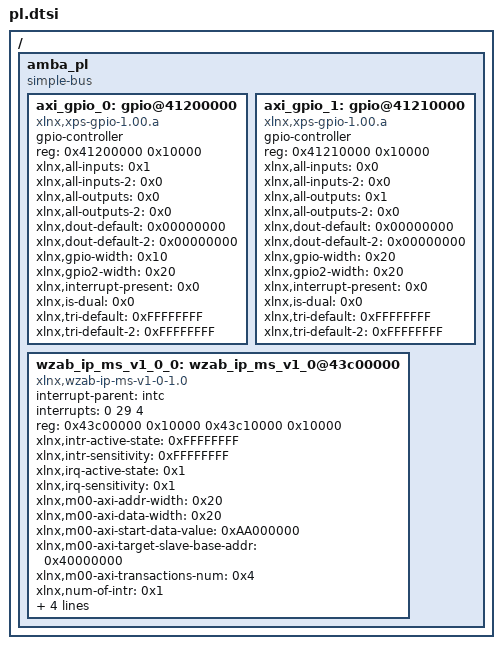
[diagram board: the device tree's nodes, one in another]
/*
 * CAUTION: This file is automatically generated by Xilinx.
 * Version:  
 * Today is: Fri Aug 12 16:10:27 2016
*/


/ {
	amba_pl: amba_pl {
		#address-cells = <1>;
		#size-cells = <1>;
		compatible = "simple-bus";
		ranges ;
		axi_gpio_0: gpio@41200000 {
			#gpio-cells = <2>;
			compatible = "xlnx,xps-gpio-1.00.a";
			gpio-controller ;
			reg = <0x41200000 0x10000>;
			xlnx,all-inputs = <0x1>;
			xlnx,all-inputs-2 = <0x0>;
			xlnx,all-outputs = <0x0>;
			xlnx,all-outputs-2 = <0x0>;
			xlnx,dout-default = <0x00000000>;
			xlnx,dout-default-2 = <0x00000000>;
			xlnx,gpio-width = <0x10>;
			xlnx,gpio2-width = <0x20>;
			xlnx,interrupt-present = <0x0>;
			xlnx,is-dual = <0x0>;
			xlnx,tri-default = <0xFFFFFFFF>;
			xlnx,tri-default-2 = <0xFFFFFFFF>;
		};
		axi_gpio_1: gpio@41210000 {
			#gpio-cells = <2>;
			compatible = "xlnx,xps-gpio-1.00.a";
			gpio-controller ;
			reg = <0x41210000 0x10000>;
			xlnx,all-inputs = <0x0>;
			xlnx,all-inputs-2 = <0x0>;
			xlnx,all-outputs = <0x1>;
			xlnx,all-outputs-2 = <0x0>;
			xlnx,dout-default = <0x00000000>;
			xlnx,dout-default-2 = <0x00000000>;
			xlnx,gpio-width = <0x20>;
			xlnx,gpio2-width = <0x20>;
			xlnx,interrupt-present = <0x0>;
			xlnx,is-dual = <0x0>;
			xlnx,tri-default = <0xFFFFFFFF>;
			xlnx,tri-default-2 = <0xFFFFFFFF>;
		};
		wzab_ip_ms_v1_0_0: wzab_ip_ms_v1_0@43c00000 {
			compatible = "xlnx,wzab-ip-ms-v1-0-1.0";
			interrupt-parent = <&intc>;
			interrupts = <0 29 4>;
			reg = <0x43c00000 0x10000 0x43c10000 0x10000>;
			xlnx,intr-active-state = <0xFFFFFFFF>;
			xlnx,intr-sensitivity = <0xFFFFFFFF>;
			xlnx,irq-active-state = <0x1>;
			xlnx,irq-sensitivity = <0x1>;
			xlnx,m00-axi-addr-width = <0x20>;
			xlnx,m00-axi-data-width = <0x20>;
			xlnx,m00-axi-start-data-value = <0xAA000000>;
			xlnx,m00-axi-target-slave-base-addr = <0x40000000>;
			xlnx,m00-axi-transactions-num = <0x4>;
			xlnx,num-of-intr = <0x1>;
			xlnx,s-axi-intr-addr-width = <0x5>;
			xlnx,s-axi-intr-data-width = <0x20>;
			xlnx,s00-axi-addr-width = <0x4>;
			xlnx,s00-axi-data-width = <0x20>;
		};
	};
};
